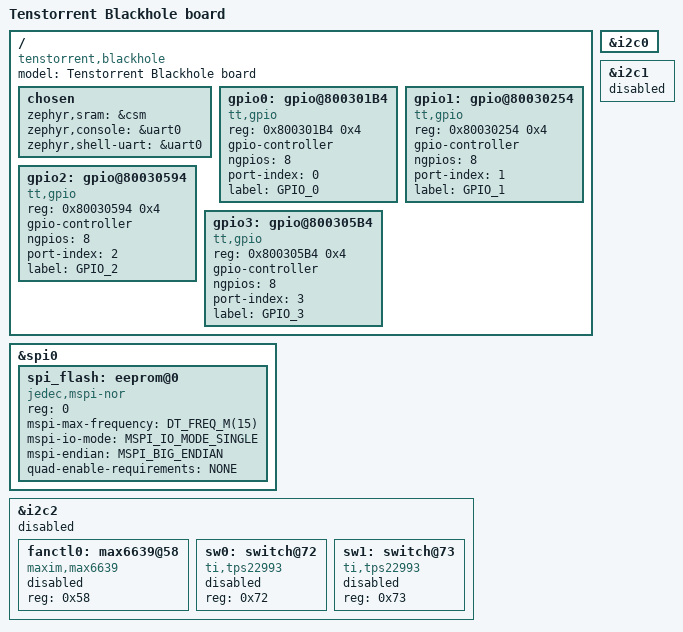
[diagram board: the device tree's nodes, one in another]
/*
 * Copyright (c) 2024 Tenstorrent AI ULC
 * SPDX-License-Identifier: Apache-2.0
 */

/dts-v1/;

#include <arc/tenstorrent/tt_blackhole_smc.dtsi>
#include "tt_blackhole-pinctrl.dtsi"

#include <freq.h>

/ {
	model = "Tenstorrent Blackhole board";
	compatible = "tenstorrent,blackhole";

	chosen {
		zephyr,sram = &csm;
		zephyr,console = &uart0;
		zephyr,shell-uart = &uart0;
	};

	gpio0: gpio@800301B4 {
		compatible = "tt,gpio";
		reg = <0x800301B4 0x4>;
		gpio-controller;
		#gpio-cells = <2>;
		ngpios = <8>;
		port-index = <0>;
		label = "GPIO_0";
	};

	gpio1: gpio@80030254 {
		compatible = "tt,gpio";
		reg = <0x80030254 0x4>;
		gpio-controller;
		#gpio-cells = <2>;
		ngpios = <8>;
		port-index = <1>;
		label = "GPIO_1";
	};

	gpio2: gpio@80030594 {
		compatible = "tt,gpio";
		reg = <0x80030594 0x4>;
		gpio-controller;
		#gpio-cells = <2>;
		ngpios = <8>;
		port-index = <2>;
		label = "GPIO_2";
	};

	gpio3: gpio@800305B4 {
		compatible = "tt,gpio";
		reg = <0x800305B4 0x4>;
		gpio-controller;
		#gpio-cells = <2>;
		ngpios = <8>;
		port-index = <3>;
		label = "GPIO_3";
	};
};

&spi0 {
	status = "okay";

	spi_flash: eeprom@0 {
		compatible = "jedec,mspi-nor";
		reg = <0>;
		status = "okay";
		/* Programming has experimentally been reliable up to 17 MHz, use 15 to be safe */
		mspi-max-frequency = <DT_FREQ_M(15)>;
		mspi-io-mode = "MSPI_IO_MODE_SINGLE";
		mspi-endian = "MSPI_BIG_ENDIAN";
		quad-enable-requirements = "NONE";
	};
};

&i2c0 {
	status = "okay";
};

&i2c1 {
	status = "disabled";
};

&i2c2 {
	status = "disabled";

	fanctl0: max6639@58 {
		compatible = "maxim,max6639";
		reg = <0x58>;
		status = "disabled";
	};

	sw0: switch@72 {
		compatible = "ti,tps22993";
		reg = <0x72>;
		status = "disabled";
	};

	sw1: switch@73 {
		compatible = "ti,tps22993";
		reg = <0x73>;
		status = "disabled";
	};
};
